# RZ/A1H register map
Vendor: Renesas
Registers are 32-bit, read-write, reset 0x0 unless marked. A register's access mark holds for its fields unless they carry their own. Offsets are from the block's base; [hi:lo] are bit positions; {n}, {i} and the like mark numbered series.

## GPIO
Base 0xFCFE3004
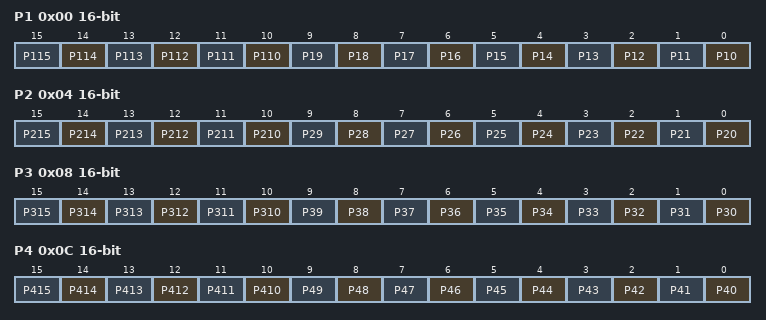
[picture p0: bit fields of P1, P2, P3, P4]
0x00 P1 16-bit
  [n-100] P{n} (n=110..115), [n-10] P{n} (n=10..19)
0x04 P2 16-bit
  [n-200] P{n} (n=210..215), [n-20] P{n} (n=20..29)
0x08 P3 16-bit
  [n-300] P{n} (n=310..315), [n-30] P{n} (n=30..39)
0x0C P4 16-bit
  [n-400] P{n} (n=410..415), [n-40] P{n} (n=40..49)
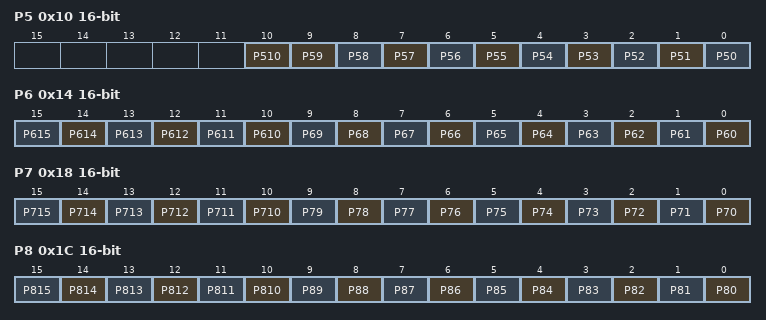
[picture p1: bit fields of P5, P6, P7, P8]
0x10 P5 16-bit
  [10] P510, [n-50] P{n} (n=50..59)
0x14 P6 16-bit
  [n-600] P{n} (n=610..615), [n-60] P{n} (n=60..69)
0x18 P7 16-bit
  [n-700] P{n} (n=710..715), [n-70] P{n} (n=70..79)
0x1C P8 16-bit
  [n-800] P{n} (n=810..815), [n-80] P{n} (n=80..89)
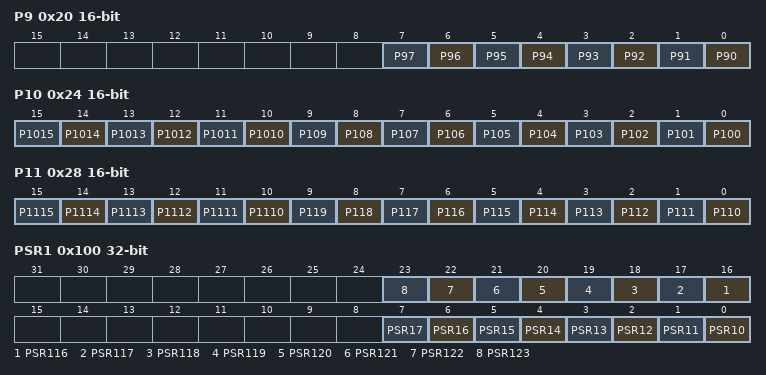
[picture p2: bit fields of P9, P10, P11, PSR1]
0x20 P9 16-bit
  [n-90] P{n} (n=90..97)
0x24 P10 16-bit
  [n-1000] P{n} (n=1010..1015), [n-100] P{n} (n=100..109)
0x28 P11 16-bit
  [n-1100] P{n} (n=1110..1115), [n-110] P{n} (n=110..119)
0x100 PSR1
  [n-100] PSR{n} (n=116..123), [n-10] PSR{n} (n=10..17)
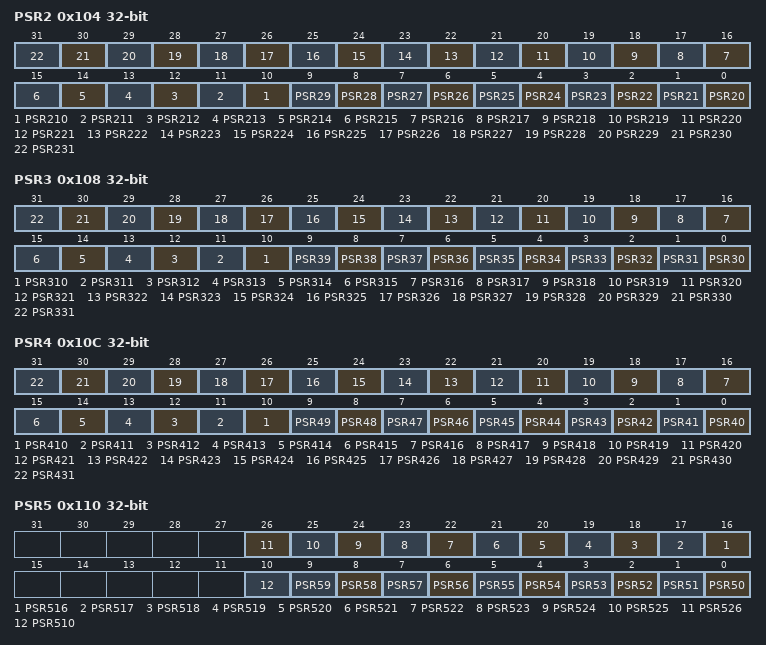
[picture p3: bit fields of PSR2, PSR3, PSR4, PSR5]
0x104 PSR2
  [n-200] PSR{n} (n=210..231), [n-20] PSR{n} (n=20..29)
0x108 PSR3
  [n-300] PSR{n} (n=310..331), [n-30] PSR{n} (n=30..39)
0x10C PSR4
  [n-400] PSR{n} (n=410..431), [n-40] PSR{n} (n=40..49)
0x110 PSR5
  [n-500] PSR{n} (n=516..526), [10] PSR510, [n-50] PSR{n} (n=50..59)
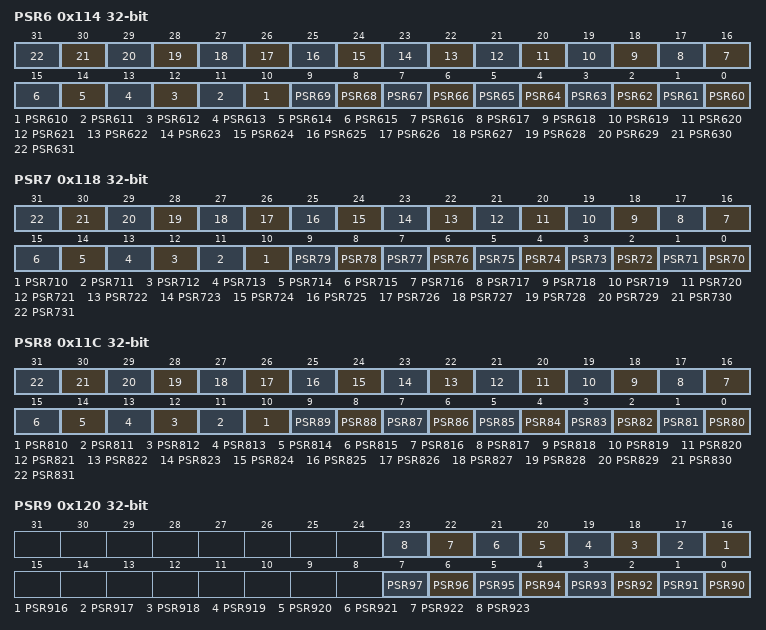
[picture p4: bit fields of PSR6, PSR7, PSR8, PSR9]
0x114 PSR6
  [n-600] PSR{n} (n=610..631), [n-60] PSR{n} (n=60..69)
0x118 PSR7
  [n-700] PSR{n} (n=710..731), [n-70] PSR{n} (n=70..79)
0x11C PSR8
  [n-800] PSR{n} (n=810..831), [n-80] PSR{n} (n=80..89)
0x120 PSR9
  [n-900] PSR{n} (n=916..923), [n-90] PSR{n} (n=90..97)
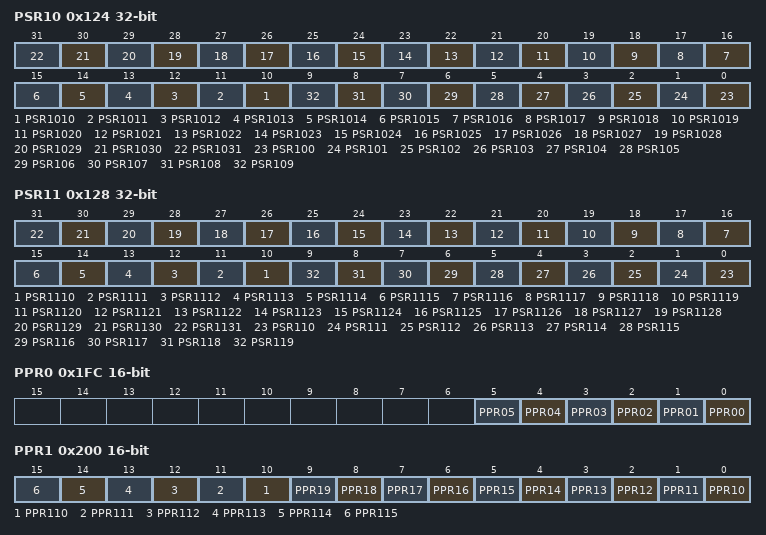
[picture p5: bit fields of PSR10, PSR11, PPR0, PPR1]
0x124 PSR10
  [n-1000] PSR{n} (n=1010..1031), [n-100] PSR{n} (n=100..109)
0x128 PSR11
  [n-1100] PSR{n} (n=1110..1131), [n-110] PSR{n} (n=110..119)
0x1FC PPR0 16-bit
  [n] PPR{n:02} (n=0..5)
0x200 PPR1 16-bit
  [n-100] PPR{n} (n=110..115), [n-10] PPR{n} (n=10..19)
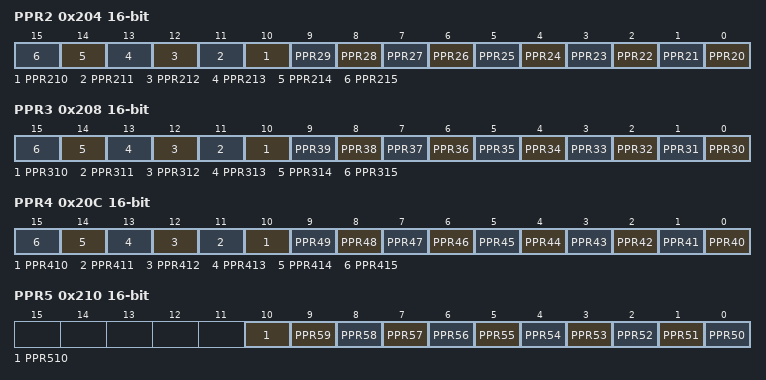
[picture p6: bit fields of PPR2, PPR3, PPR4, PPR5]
0x204 PPR2 16-bit
  [n-200] PPR{n} (n=210..215), [n-20] PPR{n} (n=20..29)
0x208 PPR3 16-bit
  [n-300] PPR{n} (n=310..315), [n-30] PPR{n} (n=30..39)
0x20C PPR4 16-bit
  [n-400] PPR{n} (n=410..415), [n-40] PPR{n} (n=40..49)
0x210 PPR5 16-bit
  [10] PPR510, [n-50] PPR{n} (n=50..59)
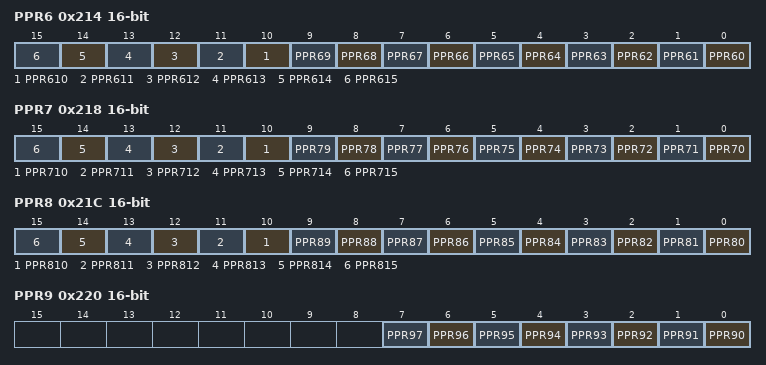
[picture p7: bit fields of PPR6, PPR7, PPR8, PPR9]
0x214 PPR6 16-bit
  [n-600] PPR{n} (n=610..615), [n-60] PPR{n} (n=60..69)
0x218 PPR7 16-bit
  [n-700] PPR{n} (n=710..715), [n-70] PPR{n} (n=70..79)
0x21C PPR8 16-bit
  [n-800] PPR{n} (n=810..815), [n-80] PPR{n} (n=80..89)
0x220 PPR9 16-bit
  [n-90] PPR{n} (n=90..97)
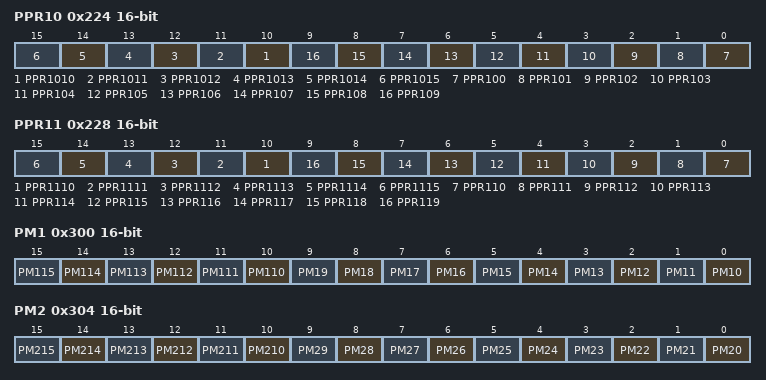
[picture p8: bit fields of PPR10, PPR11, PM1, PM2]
0x224 PPR10 16-bit
  [n-1000] PPR{n} (n=1010..1015), [n-100] PPR{n} (n=100..109)
0x228 PPR11 16-bit
  [n-1100] PPR{n} (n=1110..1115), [n-110] PPR{n} (n=110..119)
0x300 PM1 16-bit
  [n-100] PM{n} (n=110..115), [n-10] PM{n} (n=10..19)
0x304 PM2 16-bit
  [n-200] PM{n} (n=210..215), [n-20] PM{n} (n=20..29)
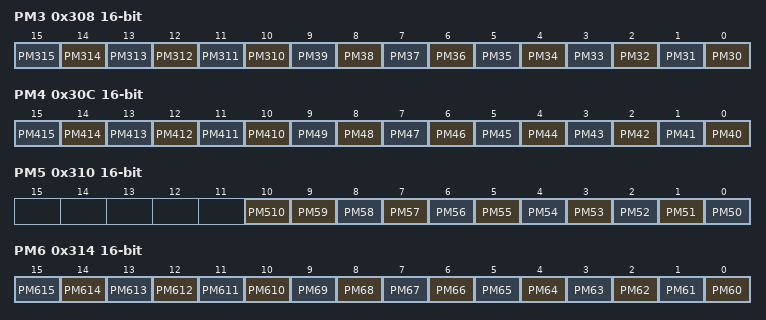
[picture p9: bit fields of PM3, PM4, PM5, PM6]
0x308 PM3 16-bit
  [n-300] PM{n} (n=310..315), [n-30] PM{n} (n=30..39)
0x30C PM4 16-bit
  [n-400] PM{n} (n=410..415), [n-40] PM{n} (n=40..49)
0x310 PM5 16-bit
  [10] PM510, [n-50] PM{n} (n=50..59)
0x314 PM6 16-bit
  [n-600] PM{n} (n=610..615), [n-60] PM{n} (n=60..69)
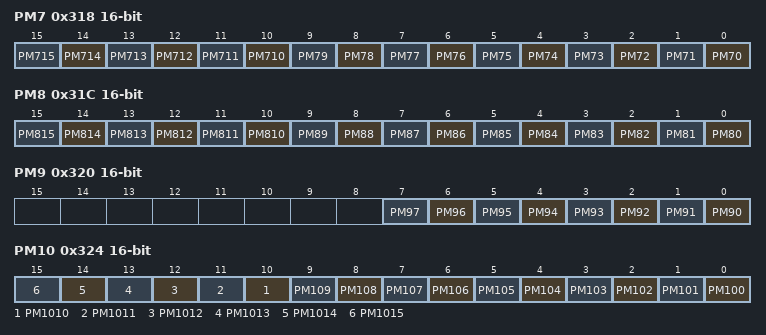
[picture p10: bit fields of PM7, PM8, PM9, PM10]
0x318 PM7 16-bit
  [n-700] PM{n} (n=710..715), [n-70] PM{n} (n=70..79)
0x31C PM8 16-bit
  [n-800] PM{n} (n=810..815), [n-80] PM{n} (n=80..89)
0x320 PM9 16-bit
  [n-90] PM{n} (n=90..97)
0x324 PM10 16-bit
  [n-1000] PM{n} (n=1010..1015), [n-100] PM{n} (n=100..109)
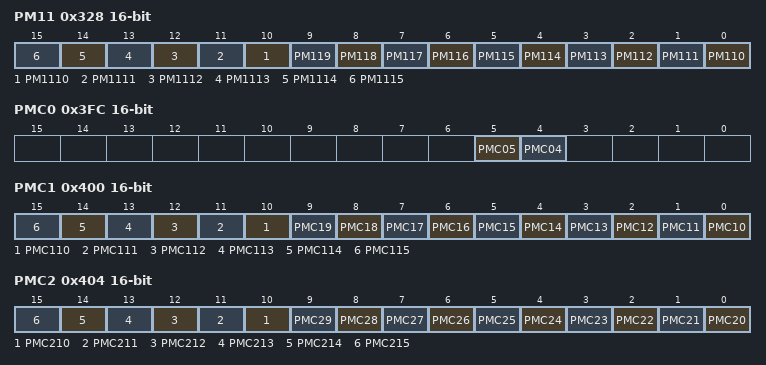
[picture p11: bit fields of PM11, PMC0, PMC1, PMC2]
0x328 PM11 16-bit
  [n-1100] PM{n} (n=1110..1115), [n-110] PM{n} (n=110..119)
0x3FC PMC0 16-bit
  [5] PMC05, [4] PMC04
0x400 PMC1 16-bit
  [n-100] PMC{n} (n=110..115), [n-10] PMC{n} (n=10..19)
0x404 PMC2 16-bit
  [n-200] PMC{n} (n=210..215), [n-20] PMC{n} (n=20..29)
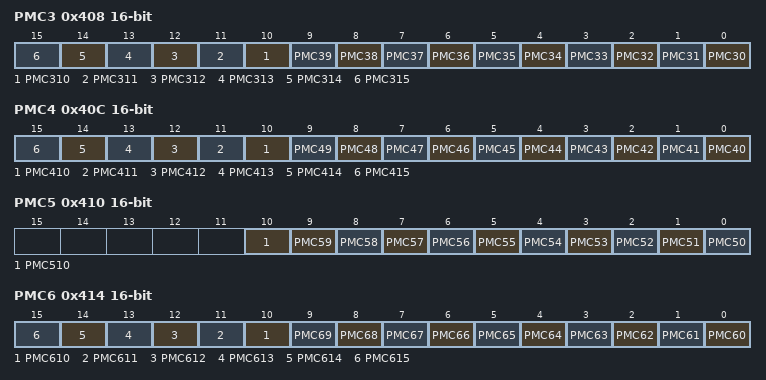
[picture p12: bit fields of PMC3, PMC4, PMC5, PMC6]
0x408 PMC3 16-bit
  [n-300] PMC{n} (n=310..315), [n-30] PMC{n} (n=30..39)
0x40C PMC4 16-bit
  [n-400] PMC{n} (n=410..415), [n-40] PMC{n} (n=40..49)
0x410 PMC5 16-bit
  [10] PMC510, [n-50] PMC{n} (n=50..59)
0x414 PMC6 16-bit
  [n-600] PMC{n} (n=610..615), [n-60] PMC{n} (n=60..69)
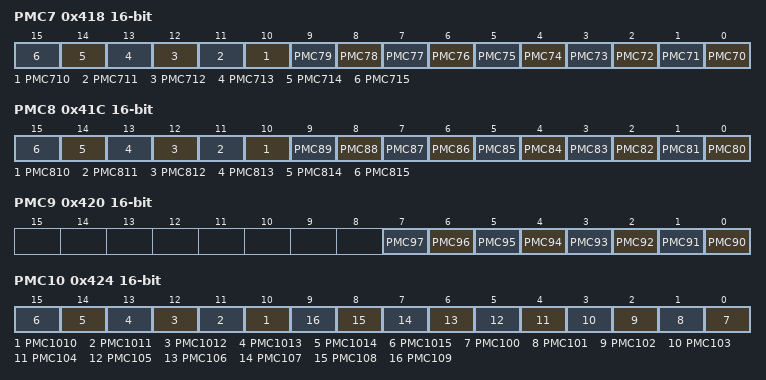
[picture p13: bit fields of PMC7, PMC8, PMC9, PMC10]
0x418 PMC7 16-bit
  [n-700] PMC{n} (n=710..715), [n-70] PMC{n} (n=70..79)
0x41C PMC8 16-bit
  [n-800] PMC{n} (n=810..815), [n-80] PMC{n} (n=80..89)
0x420 PMC9 16-bit
  [n-90] PMC{n} (n=90..97)
0x424 PMC10 16-bit
  [n-1000] PMC{n} (n=1010..1015), [n-100] PMC{n} (n=100..109)
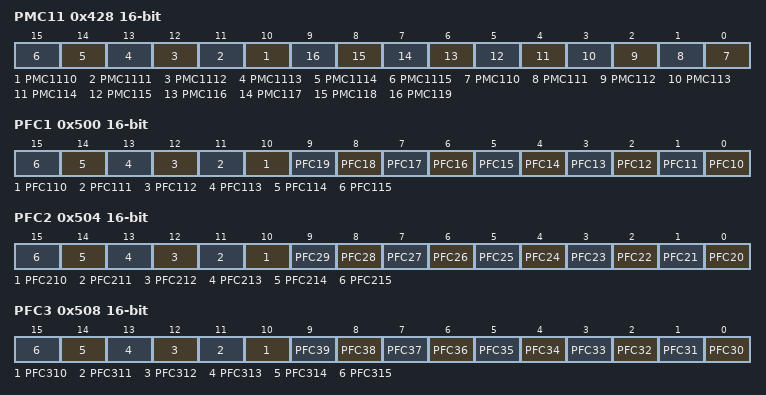
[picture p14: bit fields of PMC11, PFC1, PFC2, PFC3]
0x428 PMC11 16-bit
  [n-1100] PMC{n} (n=1110..1115), [n-110] PMC{n} (n=110..119)
0x500 PFC1 16-bit
  [n-100] PFC{n} (n=110..115), [n-10] PFC{n} (n=10..19)
0x504 PFC2 16-bit
  [n-200] PFC{n} (n=210..215), [n-20] PFC{n} (n=20..29)
0x508 PFC3 16-bit
  [n-300] PFC{n} (n=310..315), [n-30] PFC{n} (n=30..39)
0x50C PFC4 16-bit
  [n-400] PFC{n} (n=410..415), [n-40] PFC{n} (n=40..49)
0x510 PFC5 16-bit
  [10] PFC510, [n-50] PFC{n} (n=50..59)
0x514 PFC6 16-bit
  [n-600] PFC{n} (n=610..615), [n-60] PFC{n} (n=60..69)
0x518 PFC7 16-bit
  [n-700] PFC{n} (n=710..715), [n-70] PFC{n} (n=70..79)
0x51C PFC8 16-bit
  [n-800] PFC{n} (n=810..815), [n-80] PFC{n} (n=80..89)
0x520 PFC9 16-bit
  [n-90] PFC{n} (n=90..97)
0x524 PFC10 16-bit
  [n-1000] PFC{n} (n=1010..1015), [n-100] PFC{n} (n=100..109)
0x528 PFC11 16-bit
  [n-1100] PFC{n} (n=1110..1115), [n-110] PFC{n} (n=110..119)
0x600 PFCE1 16-bit
  [n-100] PFCE{n} (n=110..115), [n-10] PFCE{n} (n=10..19)
0x604 PFCE2 16-bit
  [n-200] PFCE{n} (n=210..215), [n-20] PFCE{n} (n=20..29)
0x608 PFCE3 16-bit
  [n-300] PFCE{n} (n=310..315), [n-30] PFCE{n} (n=30..39)
0x60C PFCE4 16-bit
  [n-400] PFCE{n} (n=410..415), [n-40] PFCE{n} (n=40..49)
0x610 PFCE5 16-bit
  [10] PFCE510, [n-50] PFCE{n} (n=50..59)
0x614 PFCE6 16-bit
  [n-600] PFCE{n} (n=610..615), [n-60] PFCE{n} (n=60..69)
0x618 PFCE7 16-bit
  [n-700] PFCE{n} (n=710..715), [n-70] PFCE{n} (n=70..79)
0x61C PFCE8 16-bit
  [n-800] PFCE{n} (n=810..815), [n-80] PFCE{n} (n=80..89)
0x620 PFCE9 16-bit
  [n-90] PFCE{n} (n=90..97)
0x624 PFCE10 16-bit
  [n-1000] PFCE{n} (n=1010..1015), [n-100] PFCE{n} (n=100..109)
0x628 PFCE11 16-bit
  [n-1100] PFCE{n} (n=1110..1115), [n-110] PFCE{n} (n=110..119)
0x700 PNOT1 16-bit
  [n-10] PNOT{n} (n=10..17)
0x704 PNOT2 16-bit
  [n-200] PNOT{n} (n=210..215), [n-20] PNOT{n} (n=20..29)
0x708 PNOT3 16-bit
  [n-300] PNOT{n} (n=310..315), [n-30] PNOT{n} (n=30..39)
0x70C PNOT4 16-bit
  [n-400] PNOT{n} (n=410..415), [n-40] PNOT{n} (n=40..49)
0x710 PNOT5 16-bit
  [10] PNOT510, [n-50] PNOT{n} (n=50..59)
0x714 PNOT6 16-bit
  [n-600] PNOT{n} (n=610..615), [n-60] PNOT{n} (n=60..69)
0x718 PNOT7 16-bit
  [n-700] PNOT{n} (n=710..715), [n-70] PNOT{n} (n=70..79)
0x71C PNOT8 16-bit
  [n-800] PNOT{n} (n=810..815), [n-80] PNOT{n} (n=80..89)
0x720 PNOT9 16-bit
  [n-90] PNOT{n} (n=90..97)
0x724 PNOT10 16-bit
  [n-1000] PNOT{n} (n=1010..1015), [n-100] PNOT{n} (n=100..109)
0x728 PNOT11 16-bit
  [n-1100] PNOT{n} (n=1110..1115), [n-110] PNOT{n} (n=110..119)
0x800 PMSR1
  [n-100] PMSR{n} (n=116..123), [n-10] PMSR{n} (n=10..17)
0x804 PMSR2
  [n-200] PMSR{n} (n=210..231), [n-20] PMSR{n} (n=20..29)
0x808 PMSR3
  [n-300] PMSR{n} (n=310..331), [n-30] PMSR{n} (n=30..39)
0x80C PMSR4
  [n-400] PMSR{n} (n=410..431), [n-40] PMSR{n} (n=40..49)
0x810 PMSR5
  [n-500] PMSR{n} (n=516..526), [10] PMSR510, [n-50] PMSR{n} (n=50..59)
0x814 PMSR6
  [n-600] PMSR{n} (n=610..631), [n-60] PMSR{n} (n=60..69)
0x818 PMSR7
  [n-700] PMSR{n} (n=710..731), [n-70] PMSR{n} (n=70..79)
0x81C PMSR8
  [n-800] PMSR{n} (n=810..831), [n-80] PMSR{n} (n=80..89)
0x820 PMSR9
  [n-900] PMSR{n} (n=916..923), [n-90] PMSR{n} (n=90..97)
0x824 PMSR10
  [n-1000] PMSR{n} (n=1010..1031), [n-100] PMSR{n} (n=100..109)
0x828 PMSR11
  [n-1100] PMSR{n} (n=1110..1131), [n-110] PMSR{n} (n=110..119)
0x8FC PMCSR0
  [5] PMCSR05, [4] PMCSR04
0x900 PMCSR1
  [n-100] PMCSR{n} (n=116..123), [n-10] PMCSR{n} (n=10..17)
0x904 PMCSR2
  [n-200] PMCSR{n} (n=210..231), [n-20] PMCSR{n} (n=20..29)
0x908 PMCSR3
  [n-300] PMCSR{n} (n=310..331), [n-30] PMCSR{n} (n=30..39)
0x90C PMCSR4
  [n-400] PMCSR{n} (n=410..431), [n-40] PMCSR{n} (n=40..49)
0x910 PMCSR5
  [n-500] PMCSR{n} (n=516..526), [10] PMCSR510, [n-50] PMCSR{n} (n=50..59)
0x914 PMCSR6
  [n-600] PMCSR{n} (n=610..631), [n-60] PMCSR{n} (n=60..69)
0x918 PMCSR7
  [n-700] PMCSR{n} (n=710..731), [n-70] PMCSR{n} (n=70..79)
0x91C PMCSR8
  [n-800] PMCSR{n} (n=810..831), [n-80] PMCSR{n} (n=80..89)
0x920 PMCSR9
  [n-900] PMCSR{n} (n=916..923), [n-90] PMCSR{n} (n=90..97)
0x924 PMCSR10
  [n-1000] PMCSR{n} (n=1010..1031), [n-100] PMCSR{n} (n=100..109)
0x928 PMCSR11
  [n-1100] PMCSR{n} (n=1110..1131), [n-110] PMCSR{n} (n=110..119)
0xA00 PFCAE1 16-bit
  [n-100] PFCAE{n} (n=110..115), [n-10] PFCAE{n} (n=10..19)
0xA04 PFCAE2 16-bit
  [n-200] PFCAE{n} (n=210..215), [n-20] PFCAE{n} (n=20..29)
0xA08 PFCAE3 16-bit
  [n-300] PFCAE{n} (n=310..315), [n-30] PFCAE{n} (n=30..39)
0xA0C PFCAE4 16-bit
  [n-400] PFCAE{n} (n=410..415), [n-40] PFCAE{n} (n=40..49)
0xA10 PFCAE5 16-bit
  [10] PFCAE510, [n-50] PFCAE{n} (n=50..59)
0xA14 PFCAE6 16-bit
  [n-600] PFCAE{n} (n=610..615), [n-60] PFCAE{n} (n=60..69)
0xA18 PFCAE7 16-bit
  [n-700] PFCAE{n} (n=710..715), [n-70] PFCAE{n} (n=70..79)
0xA1C PFCAE8 16-bit
  [n-800] PFCAE{n} (n=810..815), [n-80] PFCAE{n} (n=80..89)
0xA20 PFCAE9 16-bit
  [n-90] PFCAE{n} (n=90..97)
0xA24 PFCAE10 16-bit
  [n-1000] PFCAE{n} (n=1010..1015), [n-100] PFCAE{n} (n=100..109)
0xA28 PFCAE11 16-bit
  [n-1100] PFCAE{n} (n=1110..1115), [n-110] PFCAE{n} (n=110..119)
0xBFC SNCR
0x3FFC PIBC0 16-bit
  [n] PIBC{n:02} (n=0..5)
0x4000 PIBC1 16-bit
  [n-100] PIBC{n} (n=110..115), [n-10] PIBC{n} (n=10..19)
0x4004 PIBC2 16-bit
  [n-200] PIBC{n} (n=210..215), [n-20] PIBC{n} (n=20..29)
0x4008 PIBC3 16-bit
  [n-300] PIBC{n} (n=310..315), [n-30] PIBC{n} (n=30..39)
0x400C PIBC4 16-bit
  [n-400] PIBC{n} (n=410..415), [n-40] PIBC{n} (n=40..49)
0x4010 PIBC5 16-bit
  [10] PIBC510, [n-50] PIBC{n} (n=50..59)
0x4014 PIBC6 16-bit
  [n-600] PIBC{n} (n=610..615), [n-60] PIBC{n} (n=60..69)
0x4018 PIBC7 16-bit
  [n-700] PIBC{n} (n=710..715), [n-70] PIBC{n} (n=70..79)
0x401C PIBC8 16-bit
  [n-800] PIBC{n} (n=810..815), [n-80] PIBC{n} (n=80..89)
0x4020 PIBC9 16-bit
  [n-90] PIBC{n} (n=90..97)
0x4024 PIBC10 16-bit
  [n-1000] PIBC{n} (n=1010..1015), [n-100] PIBC{n} (n=100..109)
0x4028 PIBC11 16-bit
  [n-1100] PIBC{n} (n=1110..1115), [n-110] PIBC{n} (n=110..119)
0x4100 PBDC1 16-bit
  [n-100] PBDC{n} (n=110..115), [n-10] PBDC{n} (n=10..19)
0x4104 PBDC2 16-bit
  [n-200] PBDC{n} (n=210..215), [n-20] PBDC{n} (n=20..29)
0x4108 PBDC3 16-bit
  [n-300] PBDC{n} (n=310..315), [n-30] PBDC{n} (n=30..39)
0x410C PBDC4 16-bit
  [n-400] PBDC{n} (n=410..415), [n-40] PBDC{n} (n=40..49)
0x4110 PBDC5 16-bit
  [10] PBDC510, [n-50] PBDC{n} (n=50..59)
0x4114 PBDC6 16-bit
  [n-600] PBDC{n} (n=610..615), [n-60] PBDC{n} (n=60..69)
0x4118 PBDC7 16-bit
  [n-700] PBDC{n} (n=710..715), [n-70] PBDC{n} (n=70..79)
0x411C PBDC8 16-bit
  [n-800] PBDC{n} (n=810..815), [n-80] PBDC{n} (n=80..89)
0x4120 PBDC9 16-bit
  [n-90] PBDC{n} (n=90..97)
0x4124 PBDC10 16-bit
  [n-1000] PBDC{n} (n=1010..1015), [n-100] PBDC{n} (n=100..109)
0x4128 PBDC11 16-bit
  [n-1100] PBDC{n} (n=1110..1115), [n-110] PBDC{n} (n=110..119)
0x4200 PIPC1 16-bit
  [n-100] PIPC{n} (n=110..115), [n-10] PIPC{n} (n=10..19)
0x4204 PIPC2 16-bit
  [n-200] PIPC{n} (n=210..215), [n-20] PIPC{n} (n=20..29)
0x4208 PIPC3 16-bit
  [n-300] PIPC{n} (n=310..315), [n-30] PIPC{n} (n=30..39)
0x420C PIPC4 16-bit
  [n-400] PIPC{n} (n=410..415), [n-40] PIPC{n} (n=40..49)
0x4210 PIPC5 16-bit
  [10] PIPC510, [n-50] PIPC{n} (n=50..59)
0x4214 PIPC6 16-bit
  [n-600] PIPC{n} (n=610..615), [n-60] PIPC{n} (n=60..69)
0x4218 PIPC7 16-bit
  [n-700] PIPC{n} (n=710..715), [n-70] PIPC{n} (n=70..79)
0x421C PIPC8 16-bit
  [n-800] PIPC{n} (n=810..815), [n-80] PIPC{n} (n=80..89)
0x4220 PIPC9 16-bit
  [n-90] PIPC{n} (n=90..97)
0x4224 PIPC10 16-bit
  [n-1000] PIPC{n} (n=1010..1015), [n-100] PIPC{n} (n=100..109)
0x4228 PIPC11 16-bit
  [n-1100] PIPC{n} (n=1110..1115), [n-110] PIPC{n} (n=110..119)
0x4B1C JPPR0 16-bit
0x4B3C JPMC0 16-bit
0x4B8C JPMCSR0
0x4EFC JPIBC0 16-bit
